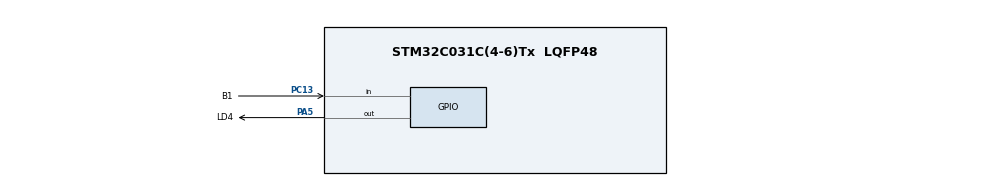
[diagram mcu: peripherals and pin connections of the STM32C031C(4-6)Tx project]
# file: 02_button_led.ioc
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Mcu.Family=STM32C0
Mcu.Name=STM32C031C(4-6)Tx
Mcu.Package=LQFP48
PA13.Mode=Serial_Wire
PA13.Signal=DEBUG_SWDIO
PA14-BOOT0.Mode=Serial_Wire
PA14-BOOT0.Signal=DEBUG_SWCLK
PA5.GPIO_Label=LD4
PA5.Signal=GPIO_Output
PC13.GPIO_Label=B1
PC13.Signal=GPIO_Input
ProjectManager.HeapSize=0x200
ProjectManager.StackSize=0x400
ProjectManager.TargetToolchain=STM32CubeIDE
RCC.ADCFreq_Value=12000000
RCC.AHBFreq_Value=12000000
RCC.CortexFreq_Value=12000000
RCC.EXTERNAL_CLOCK_VALUE=12288000
RCC.HCLKFreq_Value=12000000
RCC.HSE_VALUE=8000000
RCC.HSI_VALUE=48000000
RCC.LSE_VALUE=32768
RCC.SYSCLKFreq_VALUE=12000000
board=custom

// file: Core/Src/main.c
/* USER CODE BEGIN Header */
/**
 ******************************************************************************
 * @file           : main.c
 * @brief          : Main program body
 ******************************************************************************
 * @attention
 *
 * Copyright (c) 2026 STMicroelectronics.
 * All rights reserved.
 *
 * This software is licensed under terms that can be found in the LICENSE file
 * in the root directory of this software component.
 * If no LICENSE file comes with this software, it is provided AS-IS.
 *
 ******************************************************************************
 */
/* USER CODE END Header */
#include "main.h"

/* USER CODE BEGIN Includes */
#include "stm32c0xx_ll_gpio.h"
/* USER CODE END Includes */

/* USER CODE BEGIN PD */
#define B1_PRESSED  GPIO_PIN_RESET   // B1은 액티브 로우: 누르면 0
#define BUTTON_METHOD 1   // 1: HAL, 2: 레지스터(IDR/BSRR), 3: LL
/* USER CODE END PD */

void SystemClock_Config(void);
static void MX_GPIO_Init(void);

int main(void) {

	/* MCU Configuration--------------------------------------------------------*/

	/* Reset of all peripherals, Initializes the Flash interface and the Systick. */
	HAL_Init();

	/* Configure the system clock */
	SystemClock_Config();

	/* Initialize all configured peripherals */
	MX_GPIO_Init();

	/* Infinite loop */
	while (1) {

		/* USER CODE BEGIN 3 */
#if   BUTTON_METHOD == 1   /* HAL */
		if (HAL_GPIO_ReadPin(B1_GPIO_Port, B1_Pin) == B1_PRESSED) {
			HAL_GPIO_WritePin(LD4_GPIO_Port, LD4_Pin, GPIO_PIN_SET);
		} else {
			HAL_GPIO_WritePin(LD4_GPIO_Port, LD4_Pin, GPIO_PIN_RESET);
		}
#elif BUTTON_METHOD == 2   /* 레지스터: IDR로 읽고 BSRR로 쓰기 */
		if ((GPIOC->IDR & (1U << 13)) == 0) {   // IDR 13번 칸이 0이면 = 눌렸으면
			GPIOA->BSRR = (1U << 5);            // PA5 켜기
		} else {
			GPIOA->BSRR = (1U << 21);           // PA5 끄기
		}
#elif BUTTON_METHOD == 3   /* LL */
		if (!LL_GPIO_IsInputPinSet(B1_GPIO_Port, B1_Pin)) { // 입력이 1이 아니면 = 눌렸으면
			LL_GPIO_SetOutputPin(LD4_GPIO_Port, LD4_Pin);
		} else {
			LL_GPIO_ResetOutputPin(LD4_GPIO_Port, LD4_Pin);
		}
#endif
	}
	/* USER CODE END 3 */
}

void SystemClock_Config(void) {
	RCC_OscInitTypeDef RCC_OscInitStruct = { 0 };
	RCC_ClkInitTypeDef RCC_ClkInitStruct = { 0 };

	__HAL_FLASH_SET_LATENCY(FLASH_LATENCY_0);

	/** Initializes the RCC Oscillators according to the specified parameters
	 * in the RCC_OscInitTypeDef structure.
	 */
	RCC_OscInitStruct.OscillatorType = RCC_OSCILLATORTYPE_HSI;
	RCC_OscInitStruct.HSIState = RCC_HSI_ON;
	RCC_OscInitStruct.HSIDiv = RCC_HSI_DIV4;
	RCC_OscInitStruct.HSICalibrationValue = RCC_HSICALIBRATION_DEFAULT;
	if (HAL_RCC_OscConfig(&RCC_OscInitStruct) != HAL_OK) {
		Error_Handler();
	}

	/** Initializes the CPU, AHB and APB buses clocks
	 */
	RCC_ClkInitStruct.ClockType = RCC_CLOCKTYPE_HCLK | RCC_CLOCKTYPE_SYSCLK
			| RCC_CLOCKTYPE_PCLK1;
	RCC_ClkInitStruct.SYSCLKSource = RCC_SYSCLKSOURCE_HSI;
	RCC_ClkInitStruct.SYSCLKDivider = RCC_SYSCLK_DIV1;
	RCC_ClkInitStruct.AHBCLKDivider = RCC_HCLK_DIV1;
	RCC_ClkInitStruct.APB1CLKDivider = RCC_APB1_DIV1;

	if (HAL_RCC_ClockConfig(&RCC_ClkInitStruct, FLASH_LATENCY_0) != HAL_OK) {
		Error_Handler();
	}
}

static void MX_GPIO_Init(void) {
	GPIO_InitTypeDef GPIO_InitStruct = { 0 };

	/* GPIO Ports Clock Enable */
	__HAL_RCC_GPIOC_CLK_ENABLE();
	__HAL_RCC_GPIOA_CLK_ENABLE();

	/*Configure GPIO pin Output Level */
	HAL_GPIO_WritePin(LD4_GPIO_Port, LD4_Pin, GPIO_PIN_RESET);

	/*Configure GPIO pin : B1_Pin */
	GPIO_InitStruct.Pin = B1_Pin;
	GPIO_InitStruct.Mode = GPIO_MODE_INPUT;
	GPIO_InitStruct.Pull = GPIO_NOPULL;
	HAL_GPIO_Init(B1_GPIO_Port, &GPIO_InitStruct);

	/*Configure GPIO pin : LD4_Pin */
	GPIO_InitStruct.Pin = LD4_Pin;
	GPIO_InitStruct.Mode = GPIO_MODE_OUTPUT_PP;
	GPIO_InitStruct.Pull = GPIO_NOPULL;
	GPIO_InitStruct.Speed = GPIO_SPEED_FREQ_LOW;
	HAL_GPIO_Init(LD4_GPIO_Port, &GPIO_InitStruct);

}

void Error_Handler(void) {
	__disable_irq();
	while (1) {
	}
}
